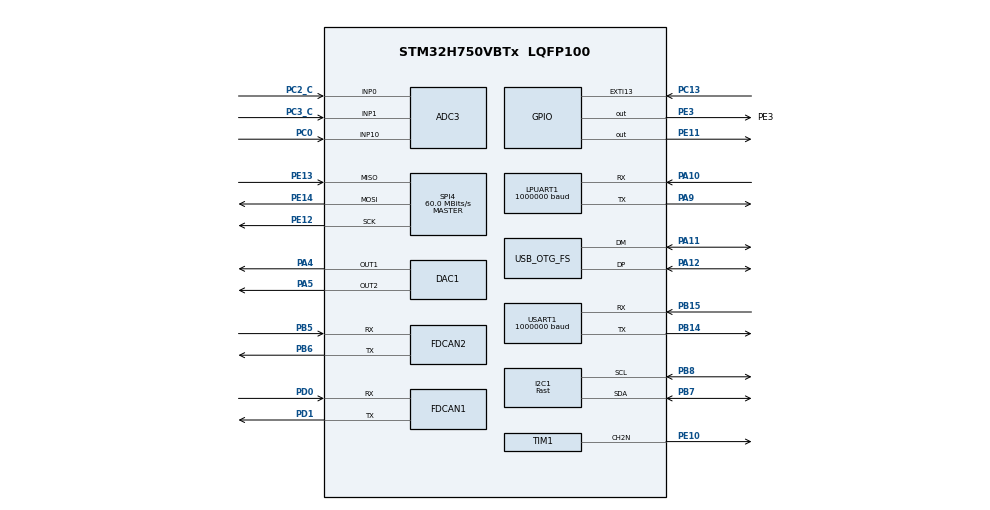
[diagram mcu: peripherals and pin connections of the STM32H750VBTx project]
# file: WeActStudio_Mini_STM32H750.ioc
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ADC3.Channel-0\#ChannelRegularConversion=ADC_CHANNEL_0
ADC3.Channel-1\#ChannelRegularConversion=ADC_CHANNEL_1
ADC3.Channel-2\#ChannelRegularConversion=ADC_CHANNEL_10
ADC3.Channel-3\#ChannelRegularConversion=ADC_CHANNEL_VBAT
ADC3.Channel-4\#ChannelRegularConversion=ADC_CHANNEL_TEMPSENSOR
ADC3.Channel-5\#ChannelRegularConversion=ADC_CHANNEL_VREFINT
ADC3.ContinuousConvMode=ENABLE
ADC3.ConversionDataManagement=ADC_CONVERSIONDATA_DMA_CIRCULAR
ADC3.EOCSelection=ADC_EOC_SINGLE_CONV
ADC3.NbrOfConversion=6
ADC3.NbrOfConversionFlag=1
ADC3.OffsetNumber-0\#ChannelRegularConversion=ADC_OFFSET_NONE
ADC3.OffsetNumber-1\#ChannelRegularConversion=ADC_OFFSET_NONE
ADC3.OffsetNumber-2\#ChannelRegularConversion=ADC_OFFSET_NONE
ADC3.OffsetNumber-3\#ChannelRegularConversion=ADC_OFFSET_NONE
ADC3.OffsetNumber-4\#ChannelRegularConversion=ADC_OFFSET_NONE
ADC3.OffsetNumber-5\#ChannelRegularConversion=ADC_OFFSET_NONE
ADC3.OffsetSignedSaturation-0\#ChannelRegularConversion=DISABLE
ADC3.OffsetSignedSaturation-1\#ChannelRegularConversion=DISABLE
ADC3.OffsetSignedSaturation-2\#ChannelRegularConversion=DISABLE
ADC3.OffsetSignedSaturation-3\#ChannelRegularConversion=DISABLE
ADC3.OffsetSignedSaturation-4\#ChannelRegularConversion=DISABLE
ADC3.OffsetSignedSaturation-5\#ChannelRegularConversion=DISABLE
ADC3.Rank-0\#ChannelRegularConversion=1
ADC3.Rank-1\#ChannelRegularConversion=2
ADC3.Rank-2\#ChannelRegularConversion=3
ADC3.Rank-3\#ChannelRegularConversion=4
ADC3.Rank-4\#ChannelRegularConversion=5
ADC3.Rank-5\#ChannelRegularConversion=6
ADC3.SamplingTime-0\#ChannelRegularConversion=ADC_SAMPLETIME_810CYCLES_5
ADC3.SamplingTime-1\#ChannelRegularConversion=ADC_SAMPLETIME_810CYCLES_5
ADC3.SamplingTime-2\#ChannelRegularConversion=ADC_SAMPLETIME_810CYCLES_5
ADC3.SamplingTime-3\#ChannelRegularConversion=ADC_SAMPLETIME_810CYCLES_5
ADC3.SamplingTime-4\#ChannelRegularConversion=ADC_SAMPLETIME_810CYCLES_5
ADC3.SamplingTime-5\#ChannelRegularConversion=ADC_SAMPLETIME_810CYCLES_5
Bdma.ADC3.2.Direction=DMA_PERIPH_TO_MEMORY
Bdma.ADC3.2.EventEnable=DISABLE
Bdma.ADC3.2.Instance=BDMA_Channel2
Bdma.ADC3.2.MemDataAlignment=DMA_MDATAALIGN_HALFWORD
Bdma.ADC3.2.MemInc=DMA_MINC_ENABLE
Bdma.ADC3.2.Mode=DMA_CIRCULAR
Bdma.ADC3.2.PeriphDataAlignment=DMA_PDATAALIGN_HALFWORD
Bdma.ADC3.2.PeriphInc=DMA_PINC_DISABLE
Bdma.ADC3.2.Polarity=HAL_DMAMUX_REQ_GEN_RISING
Bdma.ADC3.2.Priority=DMA_PRIORITY_LOW
Bdma.ADC3.2.RequestNumber=1
Bdma.ADC3.2.SignalID=NONE
Bdma.ADC3.2.SyncEnable=DISABLE
Bdma.ADC3.2.SyncPolarity=HAL_DMAMUX_SYNC_NO_EVENT
Bdma.ADC3.2.SyncRequestNumber=1
Bdma.ADC3.2.SyncSignalID=NONE
Bdma.LPUART1_RX.0.Direction=DMA_PERIPH_TO_MEMORY
Bdma.LPUART1_RX.0.EventEnable=DISABLE
Bdma.LPUART1_RX.0.Instance=BDMA_Channel0
Bdma.LPUART1_RX.0.MemDataAlignment=DMA_MDATAALIGN_BYTE
Bdma.LPUART1_RX.0.MemInc=DMA_MINC_ENABLE
Bdma.LPUART1_RX.0.Mode=DMA_NORMAL
Bdma.LPUART1_RX.0.PeriphDataAlignment=DMA_PDATAALIGN_BYTE
Bdma.LPUART1_RX.0.PeriphInc=DMA_PINC_DISABLE
Bdma.LPUART1_RX.0.Polarity=HAL_DMAMUX_REQ_GEN_RISING
Bdma.LPUART1_RX.0.Priority=DMA_PRIORITY_LOW
Bdma.LPUART1_RX.0.RequestNumber=1
Bdma.LPUART1_RX.0.SignalID=NONE
Bdma.LPUART1_RX.0.SyncEnable=DISABLE
Bdma.LPUART1_RX.0.SyncPolarity=HAL_DMAMUX_SYNC_NO_EVENT
Bdma.LPUART1_RX.0.SyncRequestNumber=1
Bdma.LPUART1_RX.0.SyncSignalID=NONE
Bdma.LPUART1_TX.1.Direction=DMA_MEMORY_TO_PERIPH
Bdma.LPUART1_TX.1.EventEnable=DISABLE
Bdma.LPUART1_TX.1.Instance=BDMA_Channel1
Bdma.LPUART1_TX.1.MemDataAlignment=DMA_MDATAALIGN_BYTE
Bdma.LPUART1_TX.1.MemInc=DMA_MINC_ENABLE
Bdma.LPUART1_TX.1.Mode=DMA_NORMAL
Bdma.LPUART1_TX.1.PeriphDataAlignment=DMA_PDATAALIGN_BYTE
Bdma.LPUART1_TX.1.PeriphInc=DMA_PINC_DISABLE
Bdma.LPUART1_TX.1.Polarity=HAL_DMAMUX_REQ_GEN_RISING
Bdma.LPUART1_TX.1.Priority=DMA_PRIORITY_LOW
Bdma.LPUART1_TX.1.RequestNumber=1
Bdma.LPUART1_TX.1.SignalID=NONE
Bdma.LPUART1_TX.1.SyncEnable=DISABLE
Bdma.LPUART1_TX.1.SyncPolarity=HAL_DMAMUX_SYNC_NO_EVENT
Bdma.LPUART1_TX.1.SyncRequestNumber=1
Bdma.LPUART1_TX.1.SyncSignalID=NONE
Bdma.Request0=LPUART1_RX
Bdma.Request1=LPUART1_TX
Bdma.Request2=ADC3
Bdma.RequestsNb=3
CORTEX_M7.CPU_DCache=Enabled
CORTEX_M7.CPU_ICache=Enabled
CORTEX_M7.Enable-Cortex_Memory_Protection_Unit_Region0_Settings=MPU_REGION_ENABLE
CORTEX_M7.IsCacheable-Cortex_Memory_Protection_Unit_Region0_Settings=MPU_ACCESS_NOT_CACHEABLE
CORTEX_M7.MPU_Control=__NULL
DAC1.DAC_Channel-DAC_OUT1=DAC_CHANNEL_1
DAC1.DAC_Channel-DAC_OUT2_ExtAndInt=DAC_CHANNEL_2
Dma.I2C1_RX.2.Direction=DMA_PERIPH_TO_MEMORY
Dma.I2C1_RX.2.EventEnable=DISABLE
Dma.I2C1_RX.2.FIFOMode=DMA_FIFOMODE_DISABLE
Dma.I2C1_RX.2.Instance=DMA1_Stream2
Dma.I2C1_RX.2.MemDataAlignment=DMA_MDATAALIGN_BYTE
Dma.I2C1_RX.2.MemInc=DMA_MINC_ENABLE
Dma.I2C1_RX.2.Mode=DMA_NORMAL
Dma.I2C1_RX.2.PeriphDataAlignment=DMA_PDATAALIGN_BYTE
Dma.I2C1_RX.2.PeriphInc=DMA_PINC_DISABLE
Dma.I2C1_RX.2.Polarity=HAL_DMAMUX_REQ_GEN_RISING
Dma.I2C1_RX.2.Priority=DMA_PRIORITY_LOW
Dma.I2C1_RX.2.RequestNumber=1
Dma.I2C1_RX.2.SignalID=NONE
Dma.I2C1_RX.2.SyncEnable=DISABLE
Dma.I2C1_RX.2.SyncPolarity=HAL_DMAMUX_SYNC_NO_EVENT
Dma.I2C1_RX.2.SyncRequestNumber=1
Dma.I2C1_RX.2.SyncSignalID=NONE
Dma.I2C1_TX.3.Direction=DMA_MEMORY_TO_PERIPH
Dma.I2C1_TX.3.EventEnable=DISABLE
Dma.I2C1_TX.3.FIFOMode=DMA_FIFOMODE_DISABLE
Dma.I2C1_TX.3.Instance=DMA1_Stream3
Dma.I2C1_TX.3.MemDataAlignment=DMA_MDATAALIGN_BYTE
Dma.I2C1_TX.3.MemInc=DMA_MINC_ENABLE
Dma.I2C1_TX.3.Mode=DMA_NORMAL
Dma.I2C1_TX.3.PeriphDataAlignment=DMA_PDATAALIGN_BYTE
Dma.I2C1_TX.3.PeriphInc=DMA_PINC_DISABLE
Dma.I2C1_TX.3.Polarity=HAL_DMAMUX_REQ_GEN_RISING
Dma.I2C1_TX.3.Priority=DMA_PRIORITY_LOW
Dma.I2C1_TX.3.RequestNumber=1
Dma.I2C1_TX.3.SignalID=NONE
Dma.I2C1_TX.3.SyncEnable=DISABLE
Dma.I2C1_TX.3.SyncPolarity=HAL_DMAMUX_SYNC_NO_EVENT
Dma.I2C1_TX.3.SyncRequestNumber=1
Dma.I2C1_TX.3.SyncSignalID=NONE
Dma.Request0=SPI4_RX
Dma.Request1=SPI4_TX
Dma.Request2=I2C1_RX
Dma.Request3=I2C1_TX
Dma.Request4=USART1_RX
Dma.Request5=USART1_TX
Dma.SPI4_RX.0.Direction=DMA_PERIPH_TO_MEMORY
Dma.SPI4_RX.0.EventEnable=DISABLE
Dma.SPI4_RX.0.FIFOMode=DMA_FIFOMODE_DISABLE
Dma.SPI4_RX.0.Instance=DMA1_Stream0
Dma.SPI4_RX.0.MemDataAlignment=DMA_MDATAALIGN_BYTE
Dma.SPI4_RX.0.MemInc=DMA_MINC_ENABLE
Dma.SPI4_RX.0.Mode=DMA_NORMAL
Dma.SPI4_RX.0.PeriphDataAlignment=DMA_PDATAALIGN_BYTE
Dma.SPI4_RX.0.PeriphInc=DMA_PINC_DISABLE
Dma.SPI4_RX.0.Polarity=HAL_DMAMUX_REQ_GEN_RISING
Dma.SPI4_RX.0.Priority=DMA_PRIORITY_LOW
Dma.SPI4_RX.0.RequestNumber=1
Dma.SPI4_RX.0.SignalID=NONE
Dma.SPI4_RX.0.SyncEnable=DISABLE
Dma.SPI4_RX.0.SyncPolarity=HAL_DMAMUX_SYNC_NO_EVENT
Dma.SPI4_RX.0.SyncRequestNumber=1
Dma.SPI4_RX.0.SyncSignalID=NONE
Dma.SPI4_TX.1.Direction=DMA_MEMORY_TO_PERIPH
Dma.SPI4_TX.1.EventEnable=DISABLE
Dma.SPI4_TX.1.FIFOMode=DMA_FIFOMODE_DISABLE
Dma.SPI4_TX.1.Instance=DMA1_Stream1
Dma.SPI4_TX.1.MemDataAlignment=DMA_MDATAALIGN_BYTE
Dma.SPI4_TX.1.MemInc=DMA_MINC_ENABLE
Dma.SPI4_TX.1.Mode=DMA_NORMAL
Dma.SPI4_TX.1.PeriphDataAlignment=DMA_PDATAALIGN_BYTE
Dma.SPI4_TX.1.PeriphInc=DMA_PINC_DISABLE
Dma.SPI4_TX.1.Polarity=HAL_DMAMUX_REQ_GEN_RISING
Dma.SPI4_TX.1.Priority=DMA_PRIORITY_LOW
Dma.SPI4_TX.1.RequestNumber=1
Dma.SPI4_TX.1.SignalID=NONE
Dma.SPI4_TX.1.SyncEnable=DISABLE
Dma.SPI4_TX.1.SyncPolarity=HAL_DMAMUX_SYNC_NO_EVENT
Dma.SPI4_TX.1.SyncRequestNumber=1
Dma.SPI4_TX.1.SyncSignalID=NONE
Dma.USART1_RX.4.Direction=DMA_PERIPH_TO_MEMORY
Dma.USART1_RX.4.EventEnable=DISABLE
Dma.USART1_RX.4.FIFOMode=DMA_FIFOMODE_DISABLE
Dma.USART1_RX.4.Instance=DMA1_Stream4
Dma.USART1_RX.4.MemDataAlignment=DMA_MDATAALIGN_BYTE
Dma.USART1_RX.4.MemInc=DMA_MINC_ENABLE
Dma.USART1_RX.4.Mode=DMA_NORMAL
Dma.USART1_RX.4.PeriphDataAlignment=DMA_PDATAALIGN_BYTE
Dma.USART1_RX.4.PeriphInc=DMA_PINC_DISABLE
Dma.USART1_RX.4.Polarity=HAL_DMAMUX_REQ_GEN_RISING
Dma.USART1_RX.4.Priority=DMA_PRIORITY_LOW
Dma.USART1_RX.4.RequestNumber=1
Dma.USART1_RX.4.SignalID=NONE
Dma.USART1_RX.4.SyncEnable=DISABLE
Dma.USART1_RX.4.SyncPolarity=HAL_DMAMUX_SYNC_NO_EVENT
Dma.USART1_RX.4.SyncRequestNumber=1
Dma.USART1_RX.4.SyncSignalID=NONE
Dma.USART1_TX.5.Direction=DMA_MEMORY_TO_PERIPH
Dma.USART1_TX.5.EventEnable=DISABLE
Dma.USART1_TX.5.FIFOMode=DMA_FIFOMODE_DISABLE
Dma.USART1_TX.5.Instance=DMA1_Stream5
Dma.USART1_TX.5.MemDataAlignment=DMA_MDATAALIGN_BYTE
Dma.USART1_TX.5.MemInc=DMA_MINC_ENABLE
Dma.USART1_TX.5.Mode=DMA_NORMAL
Dma.USART1_TX.5.PeriphDataAlignment=DMA_PDATAALIGN_BYTE
Dma.USART1_TX.5.PeriphInc=DMA_PINC_DISABLE
Dma.USART1_TX.5.Polarity=HAL_DMAMUX_REQ_GEN_RISING
Dma.USART1_TX.5.Priority=DMA_PRIORITY_LOW
Dma.USART1_TX.5.RequestNumber=1
Dma.USART1_TX.5.SignalID=NONE
Dma.USART1_TX.5.SyncEnable=DISABLE
Dma.USART1_TX.5.SyncPolarity=HAL_DMAMUX_SYNC_NO_EVENT
Dma.USART1_TX.5.SyncRequestNumber=1
Dma.USART1_TX.5.SyncSignalID=NONE
FDCAN1.CalculateBaudRateNominal=1000000
FDCAN1.CalculateTimeBitNominal=1000
FDCAN1.CalculateTimeQuantumNominal=62.5
FDCAN1.DataPrescaler=4
FDCAN1.DataTimeSeg1=6
FDCAN1.ExtFiltersNbr=1
FDCAN1.FrameFormat=FDCAN_FRAME_FD_BRS
FDCAN1.NominalPrescaler=5
FDCAN1.NominalTimeSeg1=13
FDCAN1.NominalTimeSeg2=2
FDCAN1.RxBufferSize=FDCAN_DATA_BYTES_64
FDCAN1.RxBuffersNbr=0
FDCAN1.RxFifo0ElmtSize=FDCAN_DATA_BYTES_64
FDCAN1.RxFifo0ElmtsNbr=5
FDCAN1.RxFifo1ElmtSize=FDCAN_DATA_BYTES_64
FDCAN1.RxFifo1ElmtsNbr=0
FDCAN1.StdFiltersNbr=1
FDCAN1.TxElmtSize=FDCAN_DATA_BYTES_64
FDCAN1.TxFifoQueueElmtsNbr=5
FDCAN2.CalculateBaudRateNominal=1000000
FDCAN2.CalculateTimeBitNominal=1000
FDCAN2.CalculateTimeQuantumNominal=62.5
FDCAN2.DataPrescaler=4
FDCAN2.DataTimeSeg1=6
FDCAN2.ExtFiltersNbr=1
FDCAN2.FrameFormat=FDCAN_FRAME_FD_BRS
FDCAN2.MessageRAMOffset=1280
FDCAN2.NominalPrescaler=5
FDCAN2.NominalTimeSeg1=13
FDCAN2.NominalTimeSeg2=2
FDCAN2.RxBufferSize=FDCAN_DATA_BYTES_64
FDCAN2.RxFifo0ElmtSize=FDCAN_DATA_BYTES_64
FDCAN2.RxFifo1ElmtSize=FDCAN_DATA_BYTES_64
FDCAN2.RxFifo1ElmtsNbr=5
FDCAN2.StdFiltersNbr=1
FDCAN2.TxElmtSize=FDCAN_DATA_BYTES_64
FDCAN2.TxFifoQueueElmtsNbr=5
FREERTOS.Tasks01=defaultTask,24,3192,StartDefaultTask,Default,NULL,Dynamic,NULL,NULL
FREERTOS.configCHECK_FOR_STACK_OVERFLOW=2
FREERTOS.configRECORD_STACK_HIGH_ADDRESS=1
FREERTOS.configTOTAL_HEAP_SIZE=50000
I2C1.I2C_Speed_Mode=I2C_Fast
I2C1.Timing=0x00B03FDB
LPUART1.BaudRate=1000000
Mcu.Family=STM32H7
Mcu.Name=STM32H750VBTx
Mcu.Package=LQFP100
NVIC.BDMA_Channel0_IRQn=true\:5\:0\:false\:false\:true\:true\:false\:true\:true
NVIC.BDMA_Channel1_IRQn=true\:5\:0\:false\:false\:true\:true\:false\:true\:true
NVIC.BDMA_Channel2_IRQn=true\:5\:0\:false\:false\:true\:true\:false\:true\:true
NVIC.DMA1_Stream0_IRQn=true\:5\:0\:false\:false\:true\:true\:false\:true\:true
NVIC.DMA1_Stream1_IRQn=true\:5\:0\:false\:false\:true\:true\:false\:true\:true
NVIC.DMA1_Stream2_IRQn=true\:5\:0\:false\:false\:true\:true\:false\:true\:true
NVIC.DMA1_Stream3_IRQn=true\:5\:0\:false\:false\:true\:true\:false\:true\:true
NVIC.DMA1_Stream4_IRQn=true\:5\:0\:false\:false\:true\:true\:false\:true\:true
NVIC.DMA1_Stream5_IRQn=true\:5\:0\:false\:false\:true\:true\:false\:true\:true
NVIC.EXTI15_10_IRQn=true\:5\:0\:true\:false\:true\:false\:true\:true\:true
NVIC.FDCAN1_IT0_IRQn=true\:5\:0\:false\:false\:true\:true\:true\:true\:true
NVIC.FDCAN1_IT1_IRQn=true\:5\:0\:false\:false\:true\:true\:true\:true\:true
NVIC.FDCAN2_IT0_IRQn=true\:5\:0\:false\:false\:true\:true\:true\:true\:true
NVIC.FDCAN2_IT1_IRQn=true\:5\:0\:false\:false\:true\:true\:true\:true\:true
NVIC.I2C1_EV_IRQn=true\:5\:0\:false\:false\:true\:true\:true\:true\:true
NVIC.LPUART1_IRQn=true\:5\:0\:false\:false\:true\:true\:true\:true\:true
NVIC.OTG_FS_EP1_IN_IRQn=true\:5\:0\:false\:false\:true\:true\:true\:true\:true
NVIC.OTG_FS_EP1_OUT_IRQn=true\:5\:0\:false\:false\:true\:true\:true\:true\:true
NVIC.PriorityGroup=NVIC_PRIORITYGROUP_4
NVIC.SPI4_IRQn=true\:5\:0\:false\:false\:true\:true\:true\:true\:true
NVIC.TIM17_IRQn=true\:15\:0\:false\:false\:true\:false\:false\:true\:true
NVIC.TimeBase=TIM17_IRQn
NVIC.TimeBaseIP=TIM17
NVIC.USART1_IRQn=true\:5\:0\:false\:false\:true\:true\:true\:true\:true
PA10.Mode=Asynchronous
PA10.Signal=LPUART1_RX
PA11.Mode=Device_Only
PA11.Signal=USB_OTG_FS_DM
PA12.Mode=Device_Only
PA12.Signal=USB_OTG_FS_DP
PA13\ (JTMS/SWDIO).Mode=Serial_Wire
PA13\ (JTMS/SWDIO).Signal=DEBUG_JTMS-SWDIO
PA14\ (JTCK/SWCLK).Mode=Serial_Wire
PA14\ (JTCK/SWCLK).Signal=DEBUG_JTCK-SWCLK
PA4.Signal=COMP_DAC11_group
PA5.Signal=COMP_DAC12_group
PA9.Mode=Asynchronous
PA9.Signal=LPUART1_TX
PB14.Mode=Asynchronous
PB14.Signal=USART1_TX
PB15.Mode=Asynchronous
PB15.Signal=USART1_RX
PB5.Mode=FDCAN_Activate
PB5.Signal=FDCAN2_RX
PB6.Mode=FDCAN_Activate
PB6.Signal=FDCAN2_TX
PB7.Mode=I2C
PB7.Signal=I2C1_SDA
PB8.Mode=I2C
PB8.Signal=I2C1_SCL
PC0.Signal=ADCx_INP10
PC13.Signal=GPXTI13
PC14-OSC32_IN\ (OSC32_IN).Mode=LSE-External-Oscillator
PC14-OSC32_IN\ (OSC32_IN).Signal=RCC_OSC32_IN
PC15-OSC32_OUT\ (OSC32_OUT).Mode=LSE-External-Oscillator
PC15-OSC32_OUT\ (OSC32_OUT).Signal=RCC_OSC32_OUT
PC2_C.Mode=IN0-Single-Ended
PC2_C.Signal=ADC3_INP0
PC3_C.Mode=IN1-Single-Ended
PC3_C.Signal=ADC3_INP1
PD0.Mode=FDCAN_Activate
PD0.Signal=FDCAN1_RX
PD1.Mode=FDCAN_Activate
PD1.Signal=FDCAN1_TX
PE10.Mode=PWM Generation2 CH2N
PE10.Signal=TIM1_CH2N
PE11.Signal=GPIO_Output
PE12.Mode=Full_Duplex_Master
PE12.Signal=SPI4_SCK
PE13.Mode=Full_Duplex_Master
PE13.Signal=SPI4_MISO
PE14.Mode=Full_Duplex_Master
PE14.Signal=SPI4_MOSI
PE3.GPIO_Label=PE3
PE3.PinState=GPIO_PIN_RESET
PE3.Signal=GPIO_Output
PH0-OSC_IN\ (PH0).Mode=HSE-External-Oscillator
PH0-OSC_IN\ (PH0).Signal=RCC_OSC_IN
PH1-OSC_OUT\ (PH1).Mode=HSE-External-Oscillator
PH1-OSC_OUT\ (PH1).Signal=RCC_OSC_OUT
ProjectManager.HeapSize=0x200
ProjectManager.StackSize=0x400
ProjectManager.TargetToolchain=CMake
RCC.ADCFreq_Value=80000000
RCC.APB1Freq_Value=120000000
RCC.APB2Freq_Value=120000000
RCC.APB3Freq_Value=120000000
RCC.APB4Freq_Value=120000000
RCC.CortexFreq_Value=480000000
RCC.D1PPRE=RCC_APB3_DIV2
RCC.D2PPRE1=RCC_APB1_DIV2
RCC.D2PPRE2=RCC_APB2_DIV2
RCC.D3PPRE=RCC_APB4_DIV2
RCC.DIVM1=5
RCC.DIVM2=5
RCC.DIVN1=192
RCC.DIVN2=32
RCC.DIVQ1=20
RCC.DIVR1=4
RCC.FDCANCLockSelection=RCC_FDCANCLKSOURCE_PLL2
RCC.HCLKFreq_Value=240000000
RCC.HPRE=RCC_HCLK_DIV2
RCC.HSE_VALUE=25000000
RCC.PLLFRACN=0
RCC.PLLSourceVirtual=RCC_PLLSOURCE_HSE
RCC.ProductRev=revV
RCC.SYSCLKFreq_VALUE=480000000
RCC.SYSCLKSource=RCC_SYSCLKSOURCE_PLLCLK
RCC.USBFreq_Value=48000000
SH.ADCx_INP10.0=ADC3_INP10,IN10-Single-Ended
SH.COMP_DAC11_group.0=DAC1_OUT1,DAC_OUT1
SH.COMP_DAC12_group.0=DAC1_OUT2,DAC_OUT2_ExtAndInt
SPI4.CalculateBaudRate=60.0 MBits/s
SPI4.Direction=SPI_DIRECTION_2LINES
SPI4.Mode=SPI_MODE_MASTER
SPI4.VirtualType=VM_MASTER
TIM1.Channel-PWM\ Generation2\ CH2N=TIM_CHANNEL_2
TIM1.Period=1000-1
TIM1.Prescaler=12-1
USART1.BaudRate=1000000
USART1.VirtualMode-Asynchronous=VM_ASYNC
USB_OTG_FS.VirtualMode=Device_Only
VP_ADC3_TempSens_Input.Mode=IN-TempSens
VP_ADC3_Vbat_Input.Mode=IN-Vbat
VP_ADC3_Vref_Input.Mode=IN-Vrefint
VP_FREERTOS_VS_CMSIS_V2.Mode=CMSIS_V2
VP_MEMORYMAP_VS_MEMORYMAP.Mode=CurAppReg
VP_RNG_VS_RNG.Mode=RNG_Activate
VP_SYS_VS_tim17.Mode=TIM17
board=custom

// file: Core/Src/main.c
/* USER CODE BEGIN Header */
/**
  ******************************************************************************
  * @file           : main.c
  * @brief          : Main program body
  ******************************************************************************
  * @attention
  *
  * Copyright (c) 2025 STMicroelectronics.
  * All rights reserved.
  *
  * This software is licensed under terms that can be found in the LICENSE file
  * in the root directory of this software component.
  * If no LICENSE file comes with this software, it is provided AS-IS.
  *
  ******************************************************************************
  */
/* USER CODE END Header */
#include "main.h"
#include "cmsis_os.h"
#include "adc.h"
#include "bdma.h"
#include "dac.h"
#include "dma.h"
#include "fdcan.h"
#include "i2c.h"
#include "usart.h"
#include "rng.h"
#include "spi.h"
#include "tim.h"
#include "usb_otg.h"
#include "gpio.h"

void SystemClock_Config(void);
void PeriphCommonClock_Config(void);
void MX_FREERTOS_Init(void);

int main(void)
{

  /* Enable the CPU Cache */

  /* Enable I-Cache---------------------------------------------------------*/
  SCB_EnableICache();

  /* Enable D-Cache---------------------------------------------------------*/
  SCB_EnableDCache();

  /* MCU Configuration--------------------------------------------------------*/

  /* Reset of all peripherals, Initializes the Flash interface and the Systick. */
  HAL_Init();

  /* Configure the system clock */
  SystemClock_Config();

  /* Configure the peripherals common clocks */
  PeriphCommonClock_Config();

  /* Initialize all configured peripherals */
  MX_GPIO_Init();
  MX_BDMA_Init();
  MX_DMA_Init();
  MX_RNG_Init();
  MX_LPUART1_UART_Init();
  MX_SPI4_Init();
  MX_TIM1_Init();
  MX_I2C1_Init();
  MX_ADC3_Init();
  MX_USART1_UART_Init();
  MX_DAC1_Init();
  MX_FDCAN1_Init();
  MX_FDCAN2_Init();
  MX_USB_OTG_FS_PCD_Init();

  /* Init scheduler */
  osKernelInitialize();  /* Call init function for freertos objects (in cmsis_os2.c) */
  MX_FREERTOS_Init();

  /* Start scheduler */
  osKernelStart();

  /* We should never get here as control is now taken by the scheduler */

  /* Infinite loop */
  while (1)
  {

  }
}

void SystemClock_Config(void)
{
  RCC_OscInitTypeDef RCC_OscInitStruct = {0};
  RCC_ClkInitTypeDef RCC_ClkInitStruct = {0};

  /** Supply configuration update enable
  */
  HAL_PWREx_ConfigSupply(PWR_LDO_SUPPLY);

  /** Configure the main internal regulator output voltage
  */
  __HAL_PWR_VOLTAGESCALING_CONFIG(PWR_REGULATOR_VOLTAGE_SCALE0);

  while(!__HAL_PWR_GET_FLAG(PWR_FLAG_VOSRDY)) {}

  /** Initializes the RCC Oscillators according to the specified parameters
  * in the RCC_OscInitTypeDef structure.
  */
  RCC_OscInitStruct.OscillatorType = RCC_OSCILLATORTYPE_HSI48|RCC_OSCILLATORTYPE_HSE;
  RCC_OscInitStruct.HSEState = RCC_HSE_ON;
  RCC_OscInitStruct.HSI48State = RCC_HSI48_ON;
  RCC_OscInitStruct.PLL.PLLState = RCC_PLL_ON;
  RCC_OscInitStruct.PLL.PLLSource = RCC_PLLSOURCE_HSE;
  RCC_OscInitStruct.PLL.PLLM = 5;
  RCC_OscInitStruct.PLL.PLLN = 192;
  RCC_OscInitStruct.PLL.PLLP = 2;
  RCC_OscInitStruct.PLL.PLLQ = 20;
  RCC_OscInitStruct.PLL.PLLR = 4;
  RCC_OscInitStruct.PLL.PLLRGE = RCC_PLL1VCIRANGE_2;
  RCC_OscInitStruct.PLL.PLLVCOSEL = RCC_PLL1VCOWIDE;
  RCC_OscInitStruct.PLL.PLLFRACN = 0;
  if (HAL_RCC_OscConfig(&RCC_OscInitStruct) != HAL_OK)
  {
    Error_Handler();
  }

  /** Initializes the CPU, AHB and APB buses clocks
  */
  RCC_ClkInitStruct.ClockType = RCC_CLOCKTYPE_HCLK|RCC_CLOCKTYPE_SYSCLK
                              |RCC_CLOCKTYPE_PCLK1|RCC_CLOCKTYPE_PCLK2
                              |RCC_CLOCKTYPE_D3PCLK1|RCC_CLOCKTYPE_D1PCLK1;
  RCC_ClkInitStruct.SYSCLKSource = RCC_SYSCLKSOURCE_PLLCLK;
  RCC_ClkInitStruct.SYSCLKDivider = RCC_SYSCLK_DIV1;
  RCC_ClkInitStruct.AHBCLKDivider = RCC_HCLK_DIV2;
  RCC_ClkInitStruct.APB3CLKDivider = RCC_APB3_DIV2;
  RCC_ClkInitStruct.APB1CLKDivider = RCC_APB1_DIV2;
  RCC_ClkInitStruct.APB2CLKDivider = RCC_APB2_DIV2;
  RCC_ClkInitStruct.APB4CLKDivider = RCC_APB4_DIV2;

  if (HAL_RCC_ClockConfig(&RCC_ClkInitStruct, FLASH_LATENCY_4) != HAL_OK)
  {
    Error_Handler();
  }
}

void PeriphCommonClock_Config(void)
{
  RCC_PeriphCLKInitTypeDef PeriphClkInitStruct = {0};

  /** Initializes the peripherals clock
  */
  PeriphClkInitStruct.PeriphClockSelection = RCC_PERIPHCLK_ADC|RCC_PERIPHCLK_FDCAN;
  PeriphClkInitStruct.PLL2.PLL2M = 5;
  PeriphClkInitStruct.PLL2.PLL2N = 32;
  PeriphClkInitStruct.PLL2.PLL2P = 2;
  PeriphClkInitStruct.PLL2.PLL2Q = 2;
  PeriphClkInitStruct.PLL2.PLL2R = 2;
  PeriphClkInitStruct.PLL2.PLL2RGE = RCC_PLL2VCIRANGE_2;
  PeriphClkInitStruct.PLL2.PLL2VCOSEL = RCC_PLL2VCOMEDIUM;
  PeriphClkInitStruct.PLL2.PLL2FRACN = 0;
  PeriphClkInitStruct.FdcanClockSelection = RCC_FDCANCLKSOURCE_PLL2;
  PeriphClkInitStruct.AdcClockSelection = RCC_ADCCLKSOURCE_PLL2;
  if (HAL_RCCEx_PeriphCLKConfig(&PeriphClkInitStruct) != HAL_OK)
  {
    Error_Handler();
  }
}

void HAL_TIM_PeriodElapsedCallback(TIM_HandleTypeDef *htim)
{
  if (htim->Instance == TIM17)
  {
    HAL_IncTick();
  }
}

void Error_Handler(void)
{
  __disable_irq();
  while (1)
  {
  }
}

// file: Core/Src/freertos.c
/* USER CODE BEGIN Header */
/**
  ******************************************************************************
  * File Name          : freertos.c
  * Description        : Code for freertos applications
  ******************************************************************************
  * @attention
  *
  * Copyright (c) 2025 STMicroelectronics.
  * All rights reserved.
  *
  * This software is licensed under terms that can be found in the LICENSE file
  * in the root directory of this software component.
  * If no LICENSE file comes with this software, it is provided AS-IS.
  *
  ******************************************************************************
  */
/* USER CODE END Header */

#include "FreeRTOS.h"
#include "task.h"
#include "main.h"
#include "cmsis_os.h"

/* Definitions for defaultTask */
osThreadId_t defaultTaskHandle;
const osThreadAttr_t defaultTask_attributes = {
  .name = "defaultTask",
  .stack_size = 3192 * 4,
  .priority = (osPriority_t) osPriorityNormal,
};

void StartDefaultTask(void *argument);

void MX_FREERTOS_Init(void); /* (MISRA C 2004 rule 8.1) */

/* Hook prototypes */
void vApplicationStackOverflowHook(xTaskHandle xTask, signed char *pcTaskName);

/* USER CODE BEGIN 4 */
void vApplicationStackOverflowHook(xTaskHandle xTask, signed char *pcTaskName)
{
   /* Run time stack overflow checking is performed if
   configCHECK_FOR_STACK_OVERFLOW is defined to 1 or 2. This hook function is
   called if a stack overflow is detected. */
}
/* USER CODE END 4 */

void MX_FREERTOS_Init(void) {

  /* Create the thread(s) */
  /* creation of defaultTask */
  defaultTaskHandle = osThreadNew(StartDefaultTask, NULL, &defaultTask_attributes);

}

/* USER CODE BEGIN Header_StartDefaultTask */
#include "app_main.h"
/**
  * @brief  Function implementing the defaultTask thread.
  * @param  argument: Not used
  * @retval None
  */
/* USER CODE END Header_StartDefaultTask */
void StartDefaultTask(void *argument)
{
  /* USER CODE BEGIN StartDefaultTask */
  app_main();
  /* Infinite loop */
  for(;;)
  {
    osDelay(1);
  }
  /* USER CODE END StartDefaultTask */
}
